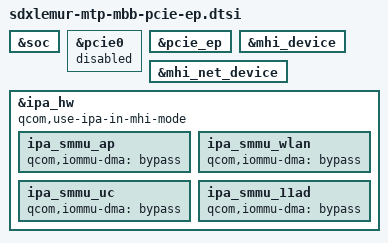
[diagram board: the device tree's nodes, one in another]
#include "sdxlemur-mtp.dtsi"
#include "sdxlemur.dtsi"

&soc {

};

&pcie0 {
	status = "disabled";
};

&pcie_ep {
	status = "ok";
};

&mhi_device {
	status = "ok";
};

&mhi_net_device {
	status = "ok";
};

&ipa_hw {
	qcom,use-ipa-in-mhi-mode;
	ipa_smmu_ap {
		qcom,iommu-dma = "bypass";
	};

	ipa_smmu_wlan {
		qcom,iommu-dma = "bypass";
	};

	ipa_smmu_uc {
		qcom,iommu-dma = "bypass";
	};

	ipa_smmu_11ad {
		qcom,iommu-dma = "bypass";
	};
};
